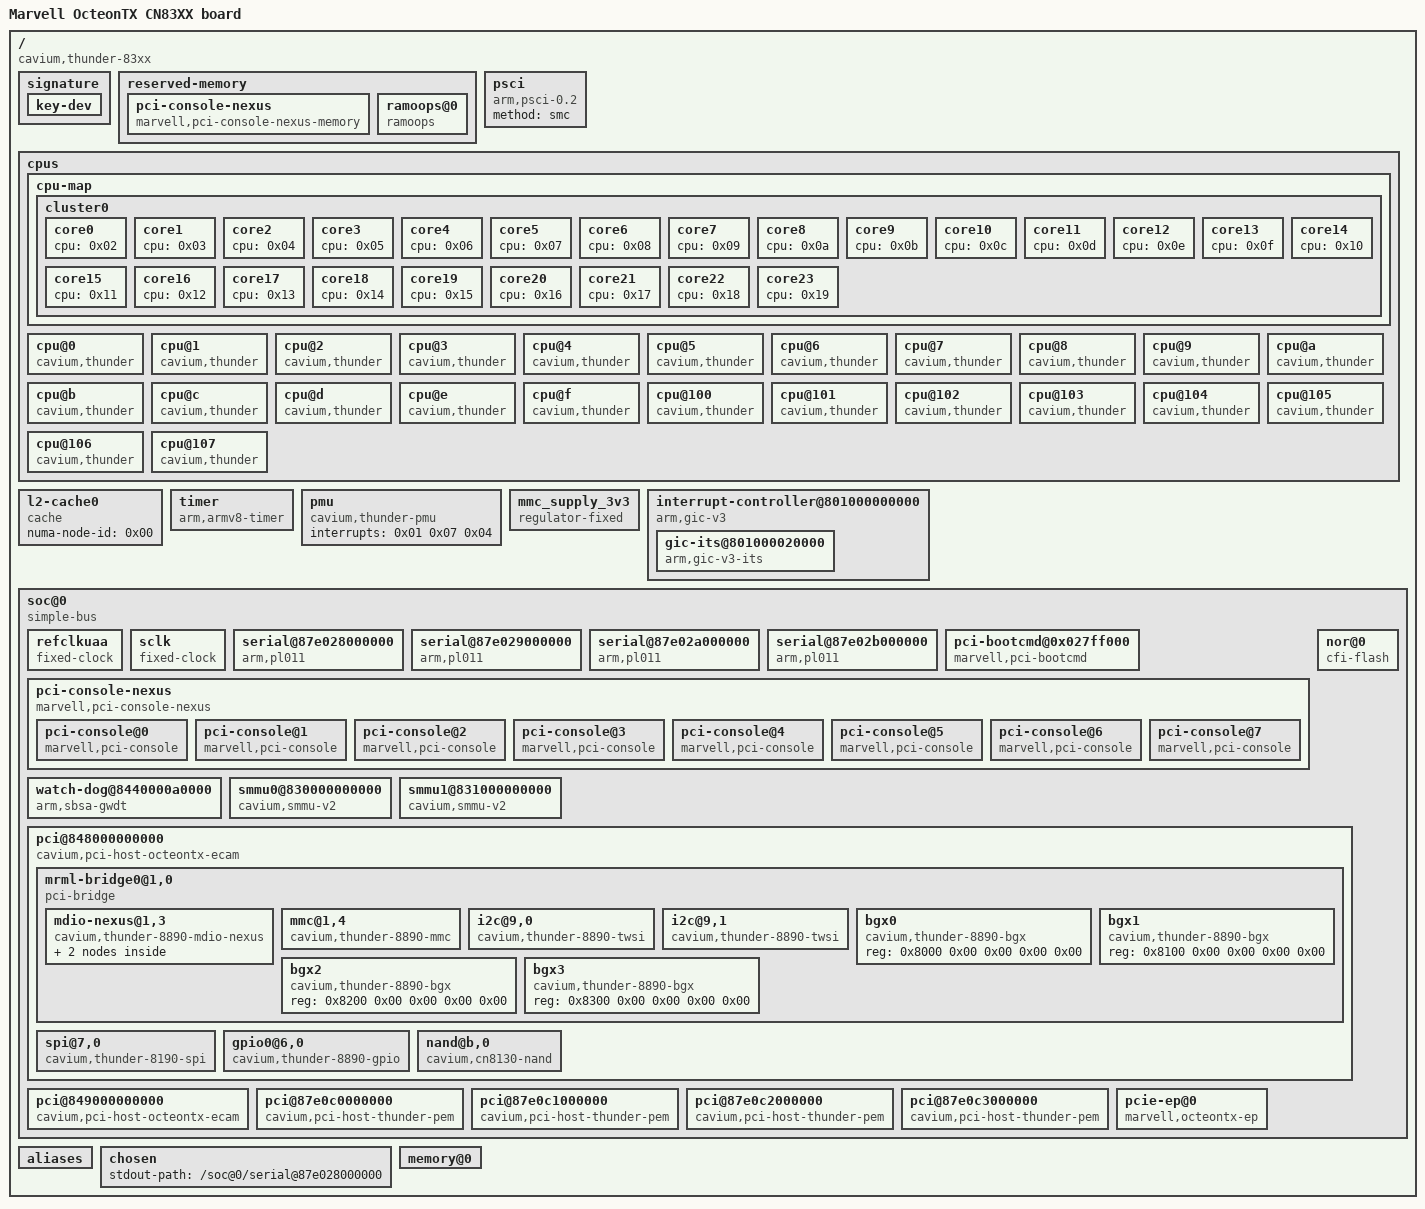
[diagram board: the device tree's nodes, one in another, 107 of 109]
/dts-v1/;

/ {
	model = "Marvell OcteonTX CN83XX board";
	compatible = "cavium,thunder-83xx";
	interrupt-parent = <0x01>;
	#address-cells = <0x02>;
	#size-cells = <0x02>;

	signature {

		key-dev {
			required = "conf";
			algo = "sha256,rsa2048";
			rsa,r-squared = <0x89ff95f2 0x851bb587 0xf73d9906 0x8a55ce4f 0x9b535633 0xd1b50060 0x519953a4 0xa6de89c3 0x4f93ceb6 0xd4845ab8 0x6a3bc081 0xf356d1da 0xedbf743c 0xa7296672 0x3dd7c1db 0x14859e3c 0x4d984c27 0x42998501 0x2b4556d5 0x7a8e7b1f 0x9f8681bc 0x966ff6fd 0x134f76f4 0x70c1dda7 0xe839ddfa 0x5af49741 0x3b6752b1 0x2d234f7e 0xf47602c2 0x7f4695da 0xd0254c2d 0xb3cea6f7 0xfed03fa5 0x2bcedae2 0x63c17224 0xf99d1673 0x5d074faf 0x2ca92fe 0xfd5f1b74 0x3c5d715b 0x761379aa 0x56237e26 0x723be51e 0xdf34595c 0xe9016c3b 0x4f50afe6 0x266a287d 0x5e855a8c 0xcd8b2745 0x772b92d 0xaaebc464 0x37da0b62 0x4efa5dea 0x5cc8e2f 0x8d9f0f5f 0x19f4d6e7 0xbda3191f 0x9cf275dd 0xe888c55a 0xe430449e 0x6f715cfe 0xd57a459f 0x6484c52a 0xca47b913>;
			rsa,modulus = <0xc9bff5e6 0x60d51523 0x9a553667 0xa341c484 0x4bd352ad 0x5b3d078a 0x19d7e80c 0x1ede28ce 0x409061b5 0xa7f3871e 0x71307b7a 0x719a585e 0xd07febbb 0x6270c0b9 0x6127e435 0x2427e020 0x811f7ebc 0x59522542 0x8f7dc73c 0x681bf21c 0x3e4848bd 0xe5d184c6 0x630f188d 0x237451d3 0xfbb6454e 0x69d59c71 0xb88eb109 0x7f89f082 0xf01b7284 0xdef8c343 0xcff96b75 0xd957c637 0x95fc81de 0x8d3bc48d 0x4c0575f7 0xfe5da80a 0x667c61b5 0x97ca0df8 0x9e54c74 0x678f983c 0xbcd24561 0xe90fec13 0x343a23fa 0xef6f5943 0xa9bf696e 0xd00eba60 0x3e5c4987 0x7b459523 0xfef707ff 0x4fc21976 0xf88e474e 0xe252bd16 0x3ec667f4 0x480c3cee 0x73aef283 0x2f9296db 0x2a53ec37 0xc6c7ec80 0xfbb49de7 0xb9bbf00b 0x11a6a24 0xc5b9cd6f 0xacab004 0x61c81afd>;
			rsa,exponent = <0x00 0x10001>;
			rsa,n0-inverse = <0xe34dadab>;
			rsa,num-bits = <0x800>;
			key-name-hint = "dev";
		};
	};

	reserved-memory {
		#address-cells = <0x02>;
		#size-cells = <0x02>;
		ranges;

		pci-console-nexus {
			compatible = "marvell,pci-console-nexus-memory";
			reg = <0x00 0x70000000 0x00 0x20100>;
			no-map;
			phandle = <0x1d>;
		};

		ramoops@0 {
			compatible = "ramoops";
			reg = <0x00 0x00 0x00 0x00>;
			record-size = <0x1000>;
			console-size = <0x1000>;
			pmsg-size = <0x1000>;
			ftrace-size = <0x1000>;
			no-map;
		};
	};

	psci {
		compatible = "arm,psci-0.2";
		method = "smc";
	};

	cpus {
		#address-cells = <0x02>;
		#size-cells = <0x00>;

		cpu-map {

			cluster0 {

				core0 {
					cpu = <0x02>;
				};

				core1 {
					cpu = <0x03>;
				};

				core2 {
					cpu = <0x04>;
				};

				core3 {
					cpu = <0x05>;
				};

				core4 {
					cpu = <0x06>;
				};

				core5 {
					cpu = <0x07>;
				};

				core6 {
					cpu = <0x08>;
				};

				core7 {
					cpu = <0x09>;
				};

				core8 {
					cpu = <0x0a>;
				};

				core9 {
					cpu = <0x0b>;
				};

				core10 {
					cpu = <0x0c>;
				};

				core11 {
					cpu = <0x0d>;
				};

				core12 {
					cpu = <0x0e>;
				};

				core13 {
					cpu = <0x0f>;
				};

				core14 {
					cpu = <0x10>;
				};

				core15 {
					cpu = <0x11>;
				};

				core16 {
					cpu = <0x12>;
				};

				core17 {
					cpu = <0x13>;
				};

				core18 {
					cpu = <0x14>;
				};

				core19 {
					cpu = <0x15>;
				};

				core20 {
					cpu = <0x16>;
				};

				core21 {
					cpu = <0x17>;
				};

				core22 {
					cpu = <0x18>;
				};

				core23 {
					cpu = <0x19>;
				};
			};
		};

		cpu@0 {
			device_type = "cpu";
			compatible = "cavium,thunder", "arm,armv8";
			reg = <0x00 0x00>;
			enable-method = "psci";
			numa-node-id = <0x00>;
			next-level-cache = <0x1a>;
			phandle = <0x02>;
		};

		cpu@1 {
			device_type = "cpu";
			compatible = "cavium,thunder", "arm,armv8";
			reg = <0x00 0x01>;
			enable-method = "psci";
			numa-node-id = <0x00>;
			next-level-cache = <0x1a>;
			phandle = <0x03>;
		};

		cpu@2 {
			device_type = "cpu";
			compatible = "cavium,thunder", "arm,armv8";
			reg = <0x00 0x02>;
			enable-method = "psci";
			numa-node-id = <0x00>;
			next-level-cache = <0x1a>;
			phandle = <0x04>;
		};

		cpu@3 {
			device_type = "cpu";
			compatible = "cavium,thunder", "arm,armv8";
			reg = <0x00 0x03>;
			enable-method = "psci";
			numa-node-id = <0x00>;
			next-level-cache = <0x1a>;
			phandle = <0x05>;
		};

		cpu@4 {
			device_type = "cpu";
			compatible = "cavium,thunder", "arm,armv8";
			reg = <0x00 0x04>;
			enable-method = "psci";
			numa-node-id = <0x00>;
			next-level-cache = <0x1a>;
			phandle = <0x06>;
		};

		cpu@5 {
			device_type = "cpu";
			compatible = "cavium,thunder", "arm,armv8";
			reg = <0x00 0x05>;
			enable-method = "psci";
			numa-node-id = <0x00>;
			next-level-cache = <0x1a>;
			phandle = <0x07>;
		};

		cpu@6 {
			device_type = "cpu";
			compatible = "cavium,thunder", "arm,armv8";
			reg = <0x00 0x06>;
			enable-method = "psci";
			numa-node-id = <0x00>;
			next-level-cache = <0x1a>;
			phandle = <0x08>;
		};

		cpu@7 {
			device_type = "cpu";
			compatible = "cavium,thunder", "arm,armv8";
			reg = <0x00 0x07>;
			enable-method = "psci";
			numa-node-id = <0x00>;
			next-level-cache = <0x1a>;
			phandle = <0x09>;
		};

		cpu@8 {
			device_type = "cpu";
			compatible = "cavium,thunder", "arm,armv8";
			reg = <0x00 0x08>;
			enable-method = "psci";
			numa-node-id = <0x00>;
			next-level-cache = <0x1a>;
			phandle = <0x0a>;
		};

		cpu@9 {
			device_type = "cpu";
			compatible = "cavium,thunder", "arm,armv8";
			reg = <0x00 0x09>;
			enable-method = "psci";
			numa-node-id = <0x00>;
			next-level-cache = <0x1a>;
			phandle = <0x0b>;
		};

		cpu@a {
			device_type = "cpu";
			compatible = "cavium,thunder", "arm,armv8";
			reg = <0x00 0x0a>;
			enable-method = "psci";
			numa-node-id = <0x00>;
			next-level-cache = <0x1a>;
			phandle = <0x0c>;
		};

		cpu@b {
			device_type = "cpu";
			compatible = "cavium,thunder", "arm,armv8";
			reg = <0x00 0x0b>;
			enable-method = "psci";
			numa-node-id = <0x00>;
			next-level-cache = <0x1a>;
			phandle = <0x0d>;
		};

		cpu@c {
			device_type = "cpu";
			compatible = "cavium,thunder", "arm,armv8";
			reg = <0x00 0x0c>;
			enable-method = "psci";
			numa-node-id = <0x00>;
			next-level-cache = <0x1a>;
			phandle = <0x0e>;
		};

		cpu@d {
			device_type = "cpu";
			compatible = "cavium,thunder", "arm,armv8";
			reg = <0x00 0x0d>;
			enable-method = "psci";
			numa-node-id = <0x00>;
			next-level-cache = <0x1a>;
			phandle = <0x0f>;
		};

		cpu@e {
			device_type = "cpu";
			compatible = "cavium,thunder", "arm,armv8";
			reg = <0x00 0x0e>;
			enable-method = "psci";
			numa-node-id = <0x00>;
			next-level-cache = <0x1a>;
			phandle = <0x10>;
		};

		cpu@f {
			device_type = "cpu";
			compatible = "cavium,thunder", "arm,armv8";
			reg = <0x00 0x0f>;
			enable-method = "psci";
			numa-node-id = <0x00>;
			next-level-cache = <0x1a>;
			phandle = <0x11>;
		};

		cpu@100 {
			device_type = "cpu";
			compatible = "cavium,thunder", "arm,armv8";
			reg = <0x00 0x100>;
			enable-method = "psci";
			numa-node-id = <0x00>;
			next-level-cache = <0x1a>;
			phandle = <0x12>;
		};

		cpu@101 {
			device_type = "cpu";
			compatible = "cavium,thunder", "arm,armv8";
			reg = <0x00 0x101>;
			enable-method = "psci";
			numa-node-id = <0x00>;
			next-level-cache = <0x1a>;
			phandle = <0x13>;
		};

		cpu@102 {
			device_type = "cpu";
			compatible = "cavium,thunder", "arm,armv8";
			reg = <0x00 0x102>;
			enable-method = "psci";
			numa-node-id = <0x00>;
			next-level-cache = <0x1a>;
			phandle = <0x14>;
		};

		cpu@103 {
			device_type = "cpu";
			compatible = "cavium,thunder", "arm,armv8";
			reg = <0x00 0x103>;
			enable-method = "psci";
			numa-node-id = <0x00>;
			next-level-cache = <0x1a>;
			phandle = <0x15>;
		};

		cpu@104 {
			device_type = "cpu";
			compatible = "cavium,thunder", "arm,armv8";
			reg = <0x00 0x104>;
			enable-method = "psci";
			numa-node-id = <0x00>;
			next-level-cache = <0x1a>;
			phandle = <0x16>;
		};

		cpu@105 {
			device_type = "cpu";
			compatible = "cavium,thunder", "arm,armv8";
			reg = <0x00 0x105>;
			enable-method = "psci";
			numa-node-id = <0x00>;
			next-level-cache = <0x1a>;
			phandle = <0x17>;
		};

		cpu@106 {
			device_type = "cpu";
			compatible = "cavium,thunder", "arm,armv8";
			reg = <0x00 0x106>;
			enable-method = "psci";
			numa-node-id = <0x00>;
			next-level-cache = <0x1a>;
			phandle = <0x18>;
		};

		cpu@107 {
			device_type = "cpu";
			compatible = "cavium,thunder", "arm,armv8";
			reg = <0x00 0x107>;
			enable-method = "psci";
			numa-node-id = <0x00>;
			next-level-cache = <0x1a>;
			phandle = <0x19>;
		};
	};

	l2-cache0 {
		compatible = "cache";
		numa-node-id = <0x00>;
		phandle = <0x1a>;
	};

	timer {
		compatible = "arm,armv8-timer";
		interrupts = <0x01 0x0d 0x04 0x01 0x0e 0x04 0x01 0x0b 0x04 0x01 0x0a 0x04>;
	};

	pmu {
		compatible = "cavium,thunder-pmu", "arm,armv8-pmuv3";
		interrupts = <0x01 0x07 0x04>;
	};

	mmc_supply_3v3 {
		compatible = "regulator-fixed";
		regulator-name = "mmc_supply_3v3";
		regulator-min-microvolt = <0x325aa0>;
		regulator-max-microvolt = <0x325aa0>;
		gpio = <0x1b 0x08 0x00>;
		enable-active-high;
		phandle = <0x22>;
	};

	interrupt-controller@801000000000 {
		compatible = "arm,gic-v3";
		#interrupt-cells = <0x03>;
		#address-cells = <0x02>;
		#size-cells = <0x02>;
		#redistributor-regions = <0x01>;
		ranges;
		interrupt-controller;
		reg = <0x8010 0x00 0x00 0x10000 0x8010 0x80000000 0x00 0x600000>;
		interrupts = <0x01 0x09 0x04>;
		phandle = <0x01>;

		gic-its@801000020000 {
			compatible = "arm,gic-v3-its";
			reg = <0x8010 0x20000 0x00 0x200000>;
			msi-controller;
			numa-node-id = <0x00>;
			phandle = <0x1f>;
		};
	};

	soc@0 {
		compatible = "simple-bus";
		sdk-version = "SDK12.23.12";
		#address-cells = <0x02>;
		#size-cells = <0x02>;
		ranges;
		numa-node-id = <0x00>;

		refclkuaa {
			compatible = "fixed-clock";
			#clock-cells = <0x00>;
			clock-frequency = <0x6f3c900>;
			clock-output-names = "refclkuaa";
			phandle = <0x1c>;
		};

		sclk {
			compatible = "fixed-clock";
			#clock-cells = <0x00>;
			clock-frequency = <0x2faf0800>;
			clock-output-names = "sclk";
			phandle = <0x1e>;
		};

		serial@87e028000000 {
			compatible = "arm,pl011", "arm,primecell";
			reg = <0x87e0 0x28000000 0x00 0x1000>;
			interrupts = <0x00 0x00 0x04>;
			clocks = <0x1c>;
			clock-names = "apb_pclk";
			skip-init;
			phandle = <0x23>;
		};

		serial@87e029000000 {
			compatible = "arm,pl011", "arm,primecell";
			reg = <0x87e0 0x29000000 0x00 0x1000>;
			interrupts = <0x00 0x01 0x04>;
			clocks = <0x1c>;
			clock-names = "apb_pclk";
			skip-init;
			phandle = <0x24>;
		};

		serial@87e02a000000 {
			compatible = "arm,pl011", "arm,primecell";
			reg = <0x87e0 0x2a000000 0x00 0x1000>;
			interrupts = <0x00 0x02 0x04>;
			clocks = <0x1c>;
			clock-names = "apb_pclk";
			skip-init;
			phandle = <0x25>;
		};

		serial@87e02b000000 {
			compatible = "arm,pl011", "arm,primecell";
			reg = <0x87e0 0x2b000000 0x00 0x1000>;
			interrupts = <0x00 0x03 0x04>;
			clocks = <0x1c>;
			clock-names = "apb_pclk";
			skip-init;
			phandle = <0x26>;
		};

		pci-bootcmd@0x027ff000 {
			compatible = "marvell,pci-bootcmd";
			reg = <0x00 0x27ff000 0x00 0x1000>;
			skip-init;
			phandle = <0x27>;
		};

		pci-console-nexus {
			compatible = "marvell,pci-console-nexus";
			status = "okay";
			#address-cells = <0x02>;
			#size-cells = <0x01>;
			skip-init;
			memory-region = <0x1d>;
			num-consoles = <0x08>;
			reg = <0x00 0x70000000 0x00 0x20100>;
			ranges = <0x00 0x00 0x00 0x70000100 0x4000 0x01 0x00 0x00 0x70004100 0x4000 0x02 0x00 0x00 0x70008100 0x4000 0x03 0x00 0x00 0x7000c100 0x4000 0x04 0x00 0x00 0x70010100 0x4000 0x05 0x00 0x00 0x70014100 0x4000 0x06 0x00 0x00 0x70018100 0x4000 0x07 0x00 0x00 0x7001c100 0x4000>;

			pci-console@0 {
				compatible = "marvell,pci-console";
				status = "okay";
				reg = <0x00 0x00 0x4000>;
				tx-buffer-size = <0x3000>;
				rx-buffer-size = <0xf80>;
			};

			pci-console@1 {
				compatible = "marvell,pci-console";
				status = "okay";
				reg = <0x01 0x00 0x4000>;
				tx-buffer-size = <0x3000>;
				rx-buffer-size = <0xf80>;
			};

			pci-console@2 {
				compatible = "marvell,pci-console";
				status = "okay";
				reg = <0x02 0x00 0x4000>;
				tx-buffer-size = <0x3000>;
				rx-buffer-size = <0xf80>;
			};

			pci-console@3 {
				compatible = "marvell,pci-console";
				status = "okay";
				reg = <0x03 0x00 0x4000>;
				tx-buffer-size = <0x3000>;
				rx-buffer-size = <0xf80>;
			};

			pci-console@4 {
				compatible = "marvell,pci-console";
				status = "okay";
				reg = <0x04 0x00 0x4000>;
				tx-buffer-size = <0x3000>;
				rx-buffer-size = <0xf80>;
			};

			pci-console@5 {
				compatible = "marvell,pci-console";
				status = "okay";
				reg = <0x05 0x00 0x4000>;
				tx-buffer-size = <0x3000>;
				rx-buffer-size = <0xf80>;
			};

			pci-console@6 {
				compatible = "marvell,pci-console";
				status = "okay";
				reg = <0x06 0x00 0x4000>;
				tx-buffer-size = <0x3000>;
				rx-buffer-size = <0xf80>;
			};

			pci-console@7 {
				compatible = "marvell,pci-console";
				status = "okay";
				reg = <0x07 0x00 0x4000>;
				tx-buffer-size = <0x3000>;
				rx-buffer-size = <0xf80>;
			};
		};

		watch-dog@8440000a0000 {
			compatible = "arm,sbsa-gwdt";
			reg = <0x8440 0xa0000 0x00 0x1000 0x8440 0xb0000 0x00 0x1000>;
			interrupts = <0x00 0x04 0x04>;
			clocks = <0x1e>;
		};

		nor@0 {
			compatible = "cfi-flash";
			reg = <0x8000 0x00 0x00 0x800000>;
			device-width = <0x01>;
			bank-width = <0x01>;
			clocks = <0x1e>;
			phandle = <0x28>;
		};

		smmu0@830000000000 {
			compatible = "cavium,smmu-v2";
			reg = <0x8300 0x00 0x00 0x2000000>;
			#global-interrupts = <0x01>;
			#iommu-cells = <0x01>;
			dma-coherent;
			interrupts = <0x00 0x15 0x04 0x00 0x16 0x04 0x00 0x16 0x04 0x00 0x16 0x04 0x00 0x16 0x04 0x00 0x16 0x04 0x00 0x16 0x04 0x00 0x16 0x04 0x00 0x16 0x04 0x00 0x16 0x04 0x00 0x16 0x04 0x00 0x16 0x04 0x00 0x16 0x04 0x00 0x16 0x04 0x00 0x16 0x04 0x00 0x16 0x04 0x00 0x16 0x04 0x00 0x16 0x04 0x00 0x16 0x04 0x00 0x16 0x04 0x00 0x16 0x04 0x00 0x16 0x04 0x00 0x16 0x04 0x00 0x16 0x04 0x00 0x16 0x04 0x00 0x16 0x04 0x00 0x16 0x04 0x00 0x16 0x04 0x00 0x16 0x04 0x00 0x16 0x04 0x00 0x16 0x04 0x00 0x16 0x04 0x00 0x16 0x04 0x00 0x16 0x04 0x00 0x16 0x04 0x00 0x16 0x04 0x00 0x16 0x04 0x00 0x16 0x04 0x00 0x16 0x04 0x00 0x16 0x04 0x00 0x16 0x04 0x00 0x16 0x04 0x00 0x16 0x04 0x00 0x16 0x04 0x00 0x16 0x04 0x00 0x16 0x04 0x00 0x16 0x04 0x00 0x16 0x04 0x00 0x16 0x04 0x00 0x16 0x04 0x00 0x16 0x04 0x00 0x16 0x04 0x00 0x16 0x04 0x00 0x16 0x04 0x00 0x16 0x04 0x00 0x16 0x04 0x00 0x16 0x04 0x00 0x16 0x04 0x00 0x16 0x04 0x00 0x16 0x04 0x00 0x16 0x04 0x00 0x16 0x04 0x00 0x16 0x04 0x00 0x16 0x04 0x00 0x16 0x04 0x00 0x16 0x04 0x00 0x16 0x04 0x00 0x16 0x04 0x00 0x16 0x04 0x00 0x16 0x04 0x00 0x16 0x04 0x00 0x16 0x04 0x00 0x16 0x04 0x00 0x16 0x04 0x00 0x16 0x04 0x00 0x16 0x04 0x00 0x16 0x04 0x00 0x16 0x04 0x00 0x16 0x04 0x00 0x16 0x04 0x00 0x16 0x04 0x00 0x16 0x04 0x00 0x16 0x04 0x00 0x16 0x04 0x00 0x16 0x04 0x00 0x16 0x04 0x00 0x16 0x04 0x00 0x16 0x04 0x00 0x16 0x04 0x00 0x16 0x04 0x00 0x16 0x04 0x00 0x16 0x04 0x00 0x16 0x04 0x00 0x16 0x04 0x00 0x16 0x04 0x00 0x16 0x04 0x00 0x16 0x04 0x00 0x16 0x04 0x00 0x16 0x04 0x00 0x16 0x04 0x00 0x16 0x04 0x00 0x16 0x04 0x00 0x16 0x04 0x00 0x16 0x04 0x00 0x16 0x04 0x00 0x16 0x04 0x00 0x16 0x04 0x00 0x16 0x04 0x00 0x16 0x04 0x00 0x16 0x04 0x00 0x16 0x04 0x00 0x16 0x04 0x00 0x16 0x04 0x00 0x16 0x04 0x00 0x16 0x04 0x00 0x16 0x04 0x00 0x16 0x04 0x00 0x16 0x04 0x00 0x16 0x04 0x00 0x16 0x04 0x00 0x16 0x04 0x00 0x16 0x04 0x00 0x16 0x04 0x00 0x16 0x04 0x00 0x16 0x04 0x00 0x16 0x04 0x00 0x16 0x04 0x00 0x16 0x04 0x00 0x16 0x04>;
			phandle = <0x20>;
		};

		smmu1@831000000000 {
			compatible = "cavium,smmu-v2";
			reg = <0x8310 0x00 0x00 0x2000000>;
			#global-interrupts = <0x01>;
			#iommu-cells = <0x01>;
			dma-coherent;
			interrupts = <0x00 0x17 0x04 0x00 0x18 0x04 0x00 0x18 0x04 0x00 0x18 0x04 0x00 0x18 0x04 0x00 0x18 0x04 0x00 0x18 0x04 0x00 0x18 0x04 0x00 0x18 0x04 0x00 0x18 0x04 0x00 0x18 0x04 0x00 0x18 0x04 0x00 0x18 0x04 0x00 0x18 0x04 0x00 0x18 0x04 0x00 0x18 0x04 0x00 0x18 0x04 0x00 0x18 0x04 0x00 0x18 0x04 0x00 0x18 0x04 0x00 0x18 0x04 0x00 0x18 0x04 0x00 0x18 0x04 0x00 0x18 0x04 0x00 0x18 0x04 0x00 0x18 0x04 0x00 0x18 0x04 0x00 0x18 0x04 0x00 0x18 0x04 0x00 0x18 0x04 0x00 0x18 0x04 0x00 0x18 0x04 0x00 0x18 0x04 0x00 0x18 0x04 0x00 0x18 0x04 0x00 0x18 0x04 0x00 0x18 0x04 0x00 0x18 0x04 0x00 0x18 0x04 0x00 0x18 0x04 0x00 0x18 0x04 0x00 0x18 0x04 0x00 0x18 0x04 0x00 0x18 0x04 0x00 0x18 0x04 0x00 0x18 0x04 0x00 0x18 0x04 0x00 0x18 0x04 0x00 0x18 0x04 0x00 0x18 0x04 0x00 0x18 0x04 0x00 0x18 0x04 0x00 0x18 0x04 0x00 0x18 0x04 0x00 0x18 0x04 0x00 0x18 0x04 0x00 0x18 0x04 0x00 0x18 0x04 0x00 0x18 0x04 0x00 0x18 0x04 0x00 0x18 0x04 0x00 0x18 0x04 0x00 0x18 0x04 0x00 0x18 0x04 0x00 0x18 0x04 0x00 0x18 0x04 0x00 0x18 0x04 0x00 0x18 0x04 0x00 0x18 0x04 0x00 0x18 0x04 0x00 0x18 0x04 0x00 0x18 0x04 0x00 0x18 0x04 0x00 0x18 0x04 0x00 0x18 0x04 0x00 0x18 0x04 0x00 0x18 0x04 0x00 0x18 0x04 0x00 0x18 0x04 0x00 0x18 0x04 0x00 0x18 0x04 0x00 0x18 0x04 0x00 0x18 0x04 0x00 0x18 0x04 0x00 0x18 0x04 0x00 0x18 0x04 0x00 0x18 0x04 0x00 0x18 0x04 0x00 0x18 0x04 0x00 0x18 0x04 0x00 0x18 0x04 0x00 0x18 0x04 0x00 0x18 0x04 0x00 0x18 0x04 0x00 0x18 0x04 0x00 0x18 0x04 0x00 0x18 0x04 0x00 0x18 0x04 0x00 0x18 0x04 0x00 0x18 0x04 0x00 0x18 0x04 0x00 0x18 0x04 0x00 0x18 0x04 0x00 0x18 0x04 0x00 0x18 0x04 0x00 0x18 0x04 0x00 0x18 0x04 0x00 0x18 0x04 0x00 0x18 0x04 0x00 0x18 0x04 0x00 0x18 0x04 0x00 0x18 0x04 0x00 0x18 0x04 0x00 0x18 0x04 0x00 0x18 0x04 0x00 0x18 0x04 0x00 0x18 0x04 0x00 0x18 0x04 0x00 0x18 0x04 0x00 0x18 0x04 0x00 0x18 0x04 0x00 0x18 0x04 0x00 0x18 0x04 0x00 0x18 0x04 0x00 0x18 0x04 0x00 0x18 0x04 0x00 0x18 0x04 0x00 0x18 0x04 0x00 0x18 0x04>;
			phandle = <0x21>;
		};

		pci@848000000000 {
			compatible = "cavium,pci-host-octeontx-ecam", "pci-host-ecam-generic";
			device_type = "pci";
			msi-parent = <0x1f>;
			msi-map = <0x00 0x1f 0x00 0x10000>;
			bus-range = <0x00 0xff>;
			#size-cells = <0x02>;
			#address-cells = <0x03>;
			#stream-id-cells = <0x01>;
			iommu-map = <0x00 0x20 0x00 0x10000>;
			dma-coherent;
			reg = <0x8480 0x00 0x00 0x10000000>;
			ranges = <0x3000000 0x8030 0x00 0x8030 0x00 0x50 0x1000000 0x3000000 0x8280 0x00 0x8280 0x00 0x07 0x2000000 0x3000000 0x8400 0x800000 0x8400 0x800000 0x0f 0xfc040000 0x3000000 0x8440 0x00 0x8440 0x00 0x00 0xf100000 0x3000000 0x8580 0x00 0x8580 0x00 0xa8 0x4000000 0x3000000 0x86e0 0x00 0x86e0 0x00 0x100 0x28000000 0x3000000 0x87e0 0x40000000 0x87e0 0x40000000 0x00 0x6c800000 0x3000000 0x87e0 0xd0000000 0x87e0 0xd0000000 0x10 0xaf100000 0x3000000 0x00 0x1400000 0x00 0x1400000 0x00 0xa00000>;
			phandle = <0x29>;

			mrml-bridge0@1,0 {
				compatible = "pci-bridge", "cavium,thunder-8890-mrml-bridge";
				#size-cells = <0x02>;
				#address-cells = <0x03>;
				ranges = <0x3000000 0x87e0 0x00 0x3000000 0x87e0 0x00 0x10 0x00>;
				reg = <0x800 0x00 0x00 0x00 0x00>;
				device_type = "pci";
				u-boot,dm-pre-reloc;
				phandle = <0x2a>;

				mdio-nexus@1,3 {
					compatible = "cavium,thunder-8890-mdio-nexus";
					#address-cells = <0x02>;
					#size-cells = <0x02>;
					reg = <0xb00 0x00 0x00 0x00 0x00>;
					assigned-addresses = <0x3000000 0x87e0 0x5000000 0x00 0x800000>;
					ranges = <0x87e0 0x5000000 0x3000000 0x87e0 0x5000000 0x00 0x800000>;

					mdio0@87e005003800 {
						compatible = "cavium,thunder-8890-mdio";
						#address-cells = <0x01>;
						#size-cells = <0x00>;
						reg = <0x87e0 0x5003800 0x00 0x30>;
					};

					mdio1@87e005003880 {
						compatible = "cavium,thunder-8890-mdio";
						#address-cells = <0x01>;
						#size-cells = <0x00>;
						reg = <0x87e0 0x5003880 0x00 0x30>;
					};
				};

				mmc@1,4 {
					compatible = "cavium,thunder-8890-mmc";
					reg = <0xc00 0x00 0x00 0x00 0x00>;
					#address-cells = <0x01>;
					#size-cells = <0x00>;
					clocks = <0x1e>;
					phandle = <0x2b>;
				};

				i2c@9,0 {
					#address-cells = <0x01>;
					#size-cells = <0x00>;
					compatible = "cavium,thunder-8890-twsi";
					reg = <0x4800 0x00 0x00 0x00 0x00>;
					clock-frequency = <0x186a0>;
					clocks = <0x1e>;
					u-boot,dm-pre-reloc;
					phandle = <0x2c>;
				};

				i2c@9,1 {
					#address-cells = <0x01>;
					#size-cells = <0x00>;
					compatible = "cavium,thunder-8890-twsi";
					reg = <0x4900 0x00 0x00 0x00 0x00>;
					clock-frequency = <0x186a0>;
					clocks = <0x1e>;
					u-boot,dm-pre-reloc;
					phandle = <0x2d>;
				};

				bgx0 {
					#address-cells = <0x01>;
					#size-cells = <0x00>;
					compatible = "cavium,thunder-8890-bgx";
					reg = <0x8000 0x00 0x00 0x00 0x00>;
				};

				bgx1 {
					#address-cells = <0x01>;
					#size-cells = <0x00>;
					compatible = "cavium,thunder-8890-bgx";
					reg = <0x8100 0x00 0x00 0x00 0x00>;
				};

				bgx2 {
					#address-cells = <0x01>;
					#size-cells = <0x00>;
					compatible = "cavium,thunder-8890-bgx";
					reg = <0x8200 0x00 0x00 0x00 0x00>;
				};

				bgx3 {
					#address-cells = <0x01>;
					#size-cells = <0x00>;
					compatible = "cavium,thunder-8890-bgx";
					reg = <0x8300 0x00 0x00 0x00 0x00>;
				};
			};

			spi@7,0 {
				compatible = "cavium,thunder-8190-spi";
				reg = <0x3800 0x00 0x00 0x00 0x00>;
				#address-cells = <0x01>;
				#size-cells = <0x00>;
				clocks = <0x1e>;
				phandle = <0x2e>;
			};

			gpio0@6,0 {
				#gpio-cells = <0x02>;
				compatible = "cavium,thunder-8890-gpio";
				gpio-controller;
				reg = <0x3000 0x00 0x00 0x00 0x00>;
				interrupts = <0x00 0x1d 0x04>;
				u-boot,dm-pre-reloc;
				phandle = <0x1b>;
			};

			nand@b,0 {
				#address-cells = <0x01>;
				#size-cells = <0x00>;
				compatible = "cavium,cn8130-nand";
				reg = <0x5800 0x00 0x00 0x00 0x00>;
				clocks = <0x1e>;
				phandle = <0x2f>;
			};
		};

		pci@849000000000 {
			compatible = "cavium,pci-host-octeontx-ecam", "pci-host-ecam-generic";
			device_type = "pci";
			msi-parent = <0x1f>;
			msi-map = <0x00 0x1f 0x10000 0x10000>;
			bus-range = <0x00 0xff>;
			#size-cells = <0x02>;
			#address-cells = <0x03>;
			#stream-id-cells = <0x01>;
			iommu-map = <0x00 0x21 0x00 0x10000>;
			dma-coherent;
			reg = <0x8490 0x00 0x00 0x10000000>;
			ranges = <0x3000000 0x8090 0x00 0x8090 0x00 0xc0 0x300000 0x3000000 0x8380 0x00 0x8380 0x00 0x00 0x30800000 0x3000000 0x8430 0x00 0x8430 0x00 0x00 0xf0000000 0x3000000 0x8540 0x00 0x8540 0x00 0x04 0x2000000 0x3000000 0x8680 0x00 0x8680 0x00 0x40 0x2000000 0x3000000 0x87f1 0x80000000 0x87f1 0x80000000 0x00 0x80000000 0x3000000 0x00 0x1e00000 0x00 0x1e00000 0x00 0xa00000>;
			phandle = <0x30>;
		};

		pci@87e0c0000000 {
			compatible = "cavium,pci-host-thunder-pem";
			device_type = "pci";
			msi-parent = <0x1f>;
			msi-map = <0x00 0x1f 0x00 0x10000>;
			bus-range = <0x1f 0x57>;
			#size-cells = <0x02>;
			#address-cells = <0x03>;
			#stream-id-cells = <0x01>;
			iommu-map = <0x00 0x20 0x10000 0x10000>;
			dma-coherent;
			reg = <0x8800 0x1f000000 0x00 0x39000000 0x87e0 0xc0000000 0x00 0x1000000>;
			ranges = <0x1000000 0x00 0x00 0x8830 0x00 0x00 0x10000 0x3000000 0x00 0x10000000 0x8810 0x10000000 0x0f 0xf0000000 0x43000000 0x10 0x00 0x8820 0x00 0x10 0x00 0x3000000 0x87e0 0xc0000000 0x87e0 0xc0000000 0x00 0x1000000>;
			#interrupt-cells = <0x01>;
			interrupt-map-mask = <0x00 0x00 0x00 0x07>;
			interrupt-map = <0x00 0x00 0x00 0x01 0x01 0x00 0x00 0x00 0x05 0x04 0x00 0x00 0x00 0x02 0x01 0x00 0x00 0x00 0x06 0x04 0x00 0x00 0x00 0x03 0x01 0x00 0x00 0x00 0x07 0x04 0x00 0x00 0x00 0x04 0x01 0x00 0x00 0x00 0x08 0x04>;
			phandle = <0x31>;
		};

		pci@87e0c1000000 {
			compatible = "cavium,pci-host-thunder-pem";
			device_type = "pci";
			msi-parent = <0x1f>;
			msi-map = <0x00 0x1f 0x00 0x10000>;
			bus-range = <0x57 0x8f>;
			#size-cells = <0x02>;
			#address-cells = <0x03>;
			#stream-id-cells = <0x01>;
			iommu-map = <0x00 0x20 0x20000 0x10000>;
			dma-coherent;
			reg = <0x8840 0x57000000 0x00 0x39000000 0x87e0 0xc1000000 0x00 0x1000000>;
			ranges = <0x1000000 0x00 0x10000 0x8870 0x10000 0x00 0x10000 0x3000000 0x00 0x10000000 0x8850 0x10000000 0x0f 0xf0000000 0x43000000 0x10 0x00 0x8860 0x00 0x10 0x00 0x3000000 0x87e0 0xc1000000 0x87e0 0xc1000000 0x00 0x1000000>;
			#interrupt-cells = <0x01>;
			interrupt-map-mask = <0x00 0x00 0x00 0x07>;
			interrupt-map = <0x00 0x00 0x00 0x01 0x01 0x00 0x00 0x00 0x09 0x04 0x00 0x00 0x00 0x02 0x01 0x00 0x00 0x00 0x0a 0x04 0x00 0x00 0x00 0x03 0x01 0x00 0x00 0x00 0x0b 0x04 0x00 0x00 0x00 0x04 0x01 0x00 0x00 0x00 0x0c 0x04>;
			phandle = <0x32>;
		};

		pci@87e0c2000000 {
			compatible = "cavium,pci-host-thunder-pem";
			device_type = "pci";
			msi-parent = <0x1f>;
			msi-map = <0x00 0x1f 0x00 0x10000>;
			bus-range = <0x8f 0xc7>;
			#size-cells = <0x02>;
			#address-cells = <0x03>;
			#stream-id-cells = <0x01>;
			iommu-map = <0x00 0x20 0x30000 0x10000>;
			dma-coherent;
			reg = <0x8880 0x8f000000 0x00 0x39000000 0x87e0 0xc2000000 0x00 0x1000000>;
			ranges = <0x1000000 0x00 0x20000 0x88b0 0x20000 0x00 0x10000 0x3000000 0x00 0x10000000 0x8890 0x10000000 0x0f 0xf0000000 0x43000000 0x10 0x00 0x88a0 0x00 0x10 0x00 0x3000000 0x87e0 0xc2000000 0x87e0 0xc2000000 0x00 0x1000000>;
			#interrupt-cells = <0x01>;
			interrupt-map-mask = <0x00 0x00 0x00 0x07>;
			interrupt-map = <0x00 0x00 0x00 0x01 0x01 0x00 0x00 0x00 0x0d 0x04 0x00 0x00 0x00 0x02 0x01 0x00 0x00 0x00 0x0e 0x04 0x00 0x00 0x00 0x03 0x01 0x00 0x00 0x00 0x0f 0x04 0x00 0x00 0x00 0x04 0x01 0x00 0x00 0x00 0x10 0x04>;
			phandle = <0x33>;
		};

		pci@87e0c3000000 {
			compatible = "cavium,pci-host-thunder-pem";
			device_type = "pci";
			msi-parent = <0x1f>;
			msi-map = <0x00 0x1f 0x00 0x10000>;
			bus-range = <0xc7 0xff>;
			#size-cells = <0x02>;
			#address-cells = <0x03>;
			#stream-id-cells = <0x01>;
			iommu-map = <0x00 0x20 0x40000 0x10000>;
			dma-coherent;
			reg = <0x88c0 0xc7000000 0x00 0x39000000 0x87e0 0xc3000000 0x00 0x1000000>;
			ranges = <0x1000000 0x00 0x30000 0x88f0 0x30000 0x00 0x10000 0x3000000 0x00 0x10000000 0x88d0 0x10000000 0x0f 0xf0000000 0x43000000 0x10 0x00 0x88e0 0x00 0x10 0x00 0x3000000 0x87e0 0xc3000000 0x87e0 0xc3000000 0x00 0x1000000>;
			#interrupt-cells = <0x01>;
			interrupt-map-mask = <0x00 0x00 0x00 0x07>;
			interrupt-map = <0x00 0x00 0x00 0x01 0x01 0x00 0x00 0x00 0x11 0x04 0x00 0x00 0x00 0x02 0x01 0x00 0x00 0x00 0x12 0x04 0x00 0x00 0x00 0x03 0x01 0x00 0x00 0x00 0x13 0x04 0x00 0x00 0x00 0x04 0x01 0x00 0x00 0x00 0x14 0x04>;
			phandle = <0x34>;
		};

		pcie-ep@0 {
			compatible = "marvell,octeontx-ep";
			pem_base = <0x87e0 0xc0000000>;
			sdp_base = <0x8740 0x80000000>;
			oei_trig_addr = <0x8740 0x800000>;
			interrupts = <0x00 0x78 0x01 0x00 0x79 0x01 0x00 0x7a 0x01 0x00 0x7b 0x01 0x00 0x7c 0x01 0x00 0x7d 0x01 0x00 0x7e 0x01 0x00 0x7f 0x01>;
		};
	};

	aliases {
		serial0 = "/soc@0/serial@87e028000000";
		serial1 = "/soc@0/serial@87e029000000";
		serial2 = "/soc@0/serial@87e02a000000";
		serial3 = "/soc@0/serial@87e02b000000";
		i2c0 = "/soc@0/pci@848000000000/mrml-bridge0@1,0/i2c@9,0";
		i2c1 = "/soc@0/pci@848000000000/mrml-bridge0@1,0/i2c@9,1";
		spi0 = "/soc@0/pci@848000000000/spi@7,0";
	};

	chosen {
		stdout-path = "/soc@0/serial@87e028000000";
	};

	memory@0 {
		device_type = "memory";
		reg = <0x00 0x2800000 0x00 0x7ec00000>;
		numa-node-id = <0x00>;
	};

	__symbols__ {
		console_reserved = "/reserved-memory/pci-console-nexus";
		CPU0 = "/cpus/cpu@0";
		CPU1 = "/cpus/cpu@1";
		CPU2 = "/cpus/cpu@2";
		CPU3 = "/cpus/cpu@3";
		CPU4 = "/cpus/cpu@4";
		CPU5 = "/cpus/cpu@5";
		CPU6 = "/cpus/cpu@6";
		CPU7 = "/cpus/cpu@7";
		CPU8 = "/cpus/cpu@8";
		CPU9 = "/cpus/cpu@9";
		CPU10 = "/cpus/cpu@a";
		CPU11 = "/cpus/cpu@b";
		CPU12 = "/cpus/cpu@c";
		CPU13 = "/cpus/cpu@d";
		CPU14 = "/cpus/cpu@e";
		CPU15 = "/cpus/cpu@f";
		CPU16 = "/cpus/cpu@100";
		CPU17 = "/cpus/cpu@101";
		CPU18 = "/cpus/cpu@102";
		CPU19 = "/cpus/cpu@103";
		CPU20 = "/cpus/cpu@104";
		CPU21 = "/cpus/cpu@105";
		CPU22 = "/cpus/cpu@106";
		CPU23 = "/cpus/cpu@107";
		thunderx_L2_0 = "/l2-cache0";
		mmc_supply_3v3 = "/mmc_supply_3v3";
		gic0 = "/interrupt-controller@801000000000";
		its = "/interrupt-controller@801000000000/gic-its@801000020000";
		refclkuaa = "/soc@0/refclkuaa";
		sclk = "/soc@0/sclk";
		uaa0 = "/soc@0/serial@87e028000000";
		uaa1 = "/soc@0/serial@87e029000000";
		uaa2 = "/soc@0/serial@87e02a000000";
		uaa3 = "/soc@0/serial@87e02b000000";
		bootcmd = "/soc@0/pci-bootcmd@0x027ff000";
		pbus0 = "/soc@0/nor@0";
		smmu0 = "/soc@0/smmu0@830000000000";
		smmu1 = "/soc@0/smmu1@831000000000";
		ecam0 = "/soc@0/pci@848000000000";
		mrml_bridge = "/soc@0/pci@848000000000/mrml-bridge0@1,0";
		mmc_1_4 = "/soc@0/pci@848000000000/mrml-bridge0@1,0/mmc@1,4";
		i2c_9_0 = "/soc@0/pci@848000000000/mrml-bridge0@1,0/i2c@9,0";
		i2c_9_1 = "/soc@0/pci@848000000000/mrml-bridge0@1,0/i2c@9,1";
		spi_7_0 = "/soc@0/pci@848000000000/spi@7,0";
		gpio_6_0 = "/soc@0/pci@848000000000/gpio0@6,0";
		nfc = "/soc@0/pci@848000000000/nand@b,0";
		ecam1 = "/soc@0/pci@849000000000";
		pem0 = "/soc@0/pci@87e0c0000000";
		pem1 = "/soc@0/pci@87e0c1000000";
		pem2 = "/soc@0/pci@87e0c2000000";
		pem3 = "/soc@0/pci@87e0c3000000";
	};
};
